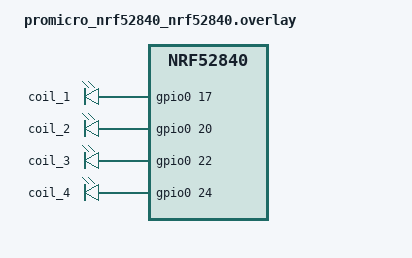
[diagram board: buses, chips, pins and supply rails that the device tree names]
/ {
  stepper_motors: stepper_motors{
    compatible = "gpio-leds";

    coil_1: coil_1 {
      gpios = <&gpio0 17 GPIO_ACTIVE_HIGH>;
    };

    coil_2: coil_2 {
      gpios = <&gpio0 20 GPIO_ACTIVE_HIGH>;
    };

    coil_3: coil_3 {
      gpios = <&gpio0 22 GPIO_ACTIVE_HIGH>;
    };

    coil_4: coil_4 {
      gpios = <&gpio0 24 GPIO_ACTIVE_HIGH>;
    };
  };
};
